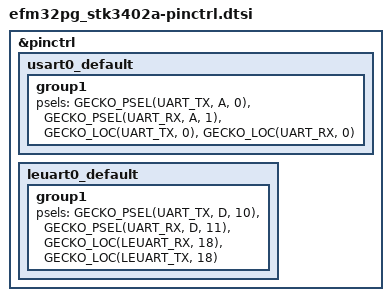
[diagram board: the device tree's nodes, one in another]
/*
 * Copyright (c) 2022 Silicon Labs
 * Copyright (c) 2023 T-Mobile USA, Inc.
 *
 * SPDX-License-Identifier: Apache-2.0
 */

#include <dt-bindings/pinctrl/gecko-pinctrl.h>

&pinctrl {
	/* configuration for usart0 device, default state - operating as UART */
	usart0_default: usart0_default {
		group1 {
			psels = <GECKO_PSEL(UART_TX, A, 0)>,
					<GECKO_PSEL(UART_RX, A, 1)>,
					<GECKO_LOC(UART_TX, 0)>,
					<GECKO_LOC(UART_RX, 0)>;
		};
	};

	/* configuration for leuart0 device */
	leuart0_default: leuart0_default {
		group1 {
			psels = <GECKO_PSEL(UART_TX, D, 10)>,
					<GECKO_PSEL(UART_RX, D, 11)>,
					<GECKO_LOC(LEUART_RX, 18)>,
					<GECKO_LOC(LEUART_TX, 18)>;
		};
	};
};
